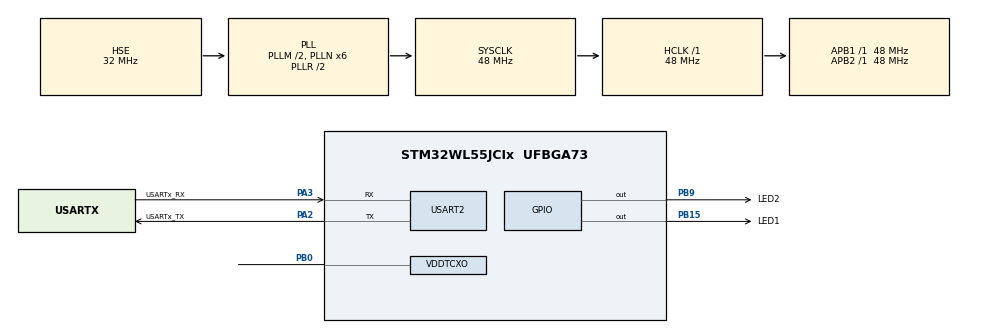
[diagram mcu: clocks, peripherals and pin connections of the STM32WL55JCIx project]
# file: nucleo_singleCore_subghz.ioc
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Mcu.Family=STM32WL
Mcu.Name=STM32WL55JCIx
Mcu.Package=UFBGA73
Mcu.UserConstants=RTC_PREDIV_A,((1<<(15-RTC_N_PREDIV_S))-1);RTC_N_PREDIV_S,10;RTC_PREDIV_S,((1<<RTC_N_PREDIV_S)-1)
NVIC.PriorityGroup=NVIC_PRIORITYGROUP_4
NVIC.SUBGHZ_Radio_IRQn=true\:0\:0\:false\:false\:true\:true\:true\:true
NVIC.USART2_IRQn=true\:0\:0\:false\:false\:true\:true\:true\:true
OSC_IN.Mode=HSE-TCXO
OSC_IN.Signal=RCC_OSC_IN
PA2.GPIO_Label=USARTx_TX
PA2.GPIO_Speed=GPIO_SPEED_FREQ_VERY_HIGH
PA2.Mode=Asynchronous
PA2.Signal=USART2_TX
PA3.GPIO_Label=USARTx_RX
PA3.GPIO_Speed=GPIO_SPEED_FREQ_VERY_HIGH
PA3.Mode=Asynchronous
PA3.Signal=USART2_RX
PB0-VDD_TCXO.Mode=HSE-TCXO
PB0-VDD_TCXO.Signal=VDDTCXO
PB15.GPIO_Label=LED1
PB15.GPIO_Speed=GPIO_SPEED_FREQ_HIGH
PB15.Signal=GPIO_Output
PB9.GPIO_Label=LED2
PB9.GPIO_Speed=GPIO_SPEED_FREQ_HIGH
PB9.Signal=GPIO_Output
PC14-OSC32_IN.Mode=LSE-External-Oscillator
PC14-OSC32_IN.Signal=RCC_OSC32_IN
PC15-OSC32_OUT.Mode=LSE-External-Oscillator
PC15-OSC32_OUT.Signal=RCC_OSC32_OUT
ProjectManager.HeapSize=0x200
ProjectManager.StackSize=0x400
ProjectManager.TargetToolchain=CMake
RCC.AHBFreq_Value=48000000
RCC.APB1Freq_Value=48000000
RCC.APB1TimFreq_Value=48000000
RCC.APB2Freq_Value=48000000
RCC.APB2TimFreq_Value=48000000
RCC.APB3Freq_Value=48000000
RCC.CortexFreq_Value=48000000
RCC.FLatency=FLASH_LATENCY_2
RCC.HCLKFreq_Value=48000000
RCC.HSE_VALUE=32000000
RCC.HSI_VALUE=16000000
RCC.LSE_VALUE=32768
RCC.MSIClockRange=RCC_MSIRANGE_11
RCC.PLLM=RCC_PLLM_DIV2
RCC.PLLN=6
RCC.PLLSourceVirtual=RCC_PLLSOURCE_HSE
RCC.PWR_Regulator_Voltage_Scale=PWR_REGULATOR_VOLTAGE_SCALE1
RCC.RTCClockSelection=RCC_RTCCLKSOURCE_LSE
RCC.SYSCLKFreq_VALUE=48000000
RCC.SYSCLKSource=RCC_SYSCLKSOURCE_PLLCLK
RCC.USART2CLockSelection=RCC_USART2CLKSOURCE_SYSCLK
RCC.VCOOutputFreq_Value=96000000
SUBGHZ.BaudratePrescaler=SUBGHZSPI_BAUDRATEPRESCALER_4
SUBGHZ_PHY.Activate_RADIO_BOARD_INTERFACE=Bsp
SUBGHZ_PHY.SUBGHZ_APPLICATION=SUBGHZ_USER_APPLICATION
SUBGHZ_PHY.USE_UART=true
SubGHz_Phy.BSP.number=1
SubGHz_Phy0.BSP.STBoard=false
SubGHz_Phy0.BSP.api=Unknown
SubGHz_Phy0.BSP.condition=\!SEM_SUBGHZ_USER_APPLICATION | SEM_SUBGHZ_USE_UART
SubGHz_Phy0.BSP.instance=USART2
SubGHz_Phy0.BSP.ip=(LPU|US)ART
SubGHz_Phy0.BSP.mode=Asynchronous
SubGHz_Phy0.BSP.name=USART
SubGHz_Phy0.BSP.solution=USART2
USART2.VirtualMode-Asynchronous=VM_ASYNC
VP_ADV_TRACE_VS_ADV_TRACE.Mode=ADV_TRACE_Enabled
VP_MISC_VS_MISC.Mode=MISC_Enabled
VP_SEQUENCER_M4_VS_SEQUENCER.Mode=SEQUENCER_Enabled
VP_SUBGHZ_PHY_VS_SubGhzPhy.Mode=SubGhzPhy_Enabled
VP_SUBGHZ_VS_SUBGHZ.Mode=SUBGHZ_Activate
VP_TIMER_VS_TIMER.Mode=TIMER_Enabled
VP_TINY_LPM_VS_TINY_LPM.Mode=TINY_LPM_Enabled
board=custom

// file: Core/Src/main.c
/* USER CODE BEGIN Header */
/**
 ******************************************************************************
 * @file           : main.c
 * @brief          : Main program body
 ******************************************************************************
 * @attention
 *
 * Copyright (c) 2026 STMicroelectronics.
 * All rights reserved.
 *
 * This software is licensed under terms that can be found in the LICENSE file
 * in the root directory of this software component.
 * If no LICENSE file comes with this software, it is provided AS-IS.
 *
 ******************************************************************************
 */
/* USER CODE END Header */
#include "main.h"
#include "app_subghz_phy.h"

/* USER CODE BEGIN Includes */
#include <stdint.h>
#include <stdio.h>
/* USER CODE END Includes */

SUBGHZ_HandleTypeDef hsubghz;

UART_HandleTypeDef huart2;

void SystemClock_Config(void);
static void MX_GPIO_Init(void);
/* USER CODE BEGIN PFP */

int __io_putchar(int ch)
{
  HAL_UART_Transmit(&huart2, (uint8_t *)&ch, 1, HAL_MAX_DELAY);
  return ch;
}

/* USER CODE END PFP */

int main(void)
{

  /* MCU Configuration--------------------------------------------------------*/

  /* Reset of all peripherals, Initializes the Flash interface and the Systick. */
  HAL_Init();

  /* Configure the system clock */
  SystemClock_Config();

  /* USER CODE BEGIN SysInit */
  MX_USART2_UART_Init();

  /* USER CODE END SysInit */

  /* Initialize all configured peripherals */
  MX_GPIO_Init();
  MX_SubGHz_Phy_Init();

  /* Infinite loop */
  while (1)
  {
    MX_SubGHz_Phy_Process();

  }
}

void SystemClock_Config(void)
{
  RCC_OscInitTypeDef RCC_OscInitStruct = {0};
  RCC_ClkInitTypeDef RCC_ClkInitStruct = {0};

  /** Configure the main internal regulator output voltage
  */
  __HAL_PWR_VOLTAGESCALING_CONFIG(PWR_REGULATOR_VOLTAGE_SCALE1);

  /** Initializes the CPU, AHB and APB buses clocks
  */
  RCC_OscInitStruct.OscillatorType = RCC_OSCILLATORTYPE_HSE;
  RCC_OscInitStruct.HSEState = RCC_HSE_BYPASS_PWR;
  RCC_OscInitStruct.HSEDiv = RCC_HSE_DIV1;
  RCC_OscInitStruct.PLL.PLLState = RCC_PLL_ON;
  RCC_OscInitStruct.PLL.PLLSource = RCC_PLLSOURCE_HSE;
  RCC_OscInitStruct.PLL.PLLM = RCC_PLLM_DIV2;
  RCC_OscInitStruct.PLL.PLLN = 6;
  RCC_OscInitStruct.PLL.PLLP = RCC_PLLP_DIV2;
  RCC_OscInitStruct.PLL.PLLR = RCC_PLLR_DIV2;
  RCC_OscInitStruct.PLL.PLLQ = RCC_PLLQ_DIV2;
  if (HAL_RCC_OscConfig(&RCC_OscInitStruct) != HAL_OK)
  {
    Error_Handler();
  }

  /** Configure the SYSCLKSource, HCLK, PCLK1 and PCLK2 clocks dividers
  */
  RCC_ClkInitStruct.ClockType = RCC_CLOCKTYPE_HCLK3|RCC_CLOCKTYPE_HCLK
                              |RCC_CLOCKTYPE_SYSCLK|RCC_CLOCKTYPE_PCLK1
                              |RCC_CLOCKTYPE_PCLK2;
  RCC_ClkInitStruct.SYSCLKSource = RCC_SYSCLKSOURCE_PLLCLK;
  RCC_ClkInitStruct.AHBCLKDivider = RCC_SYSCLK_DIV1;
  RCC_ClkInitStruct.APB1CLKDivider = RCC_HCLK_DIV1;
  RCC_ClkInitStruct.APB2CLKDivider = RCC_HCLK_DIV1;
  RCC_ClkInitStruct.AHBCLK3Divider = RCC_SYSCLK_DIV1;

  if (HAL_RCC_ClockConfig(&RCC_ClkInitStruct, FLASH_LATENCY_2) != HAL_OK)
  {
    Error_Handler();
  }
}

void MX_SUBGHZ_Init(void)
{

  hsubghz.Init.BaudratePrescaler = SUBGHZSPI_BAUDRATEPRESCALER_4;
  if (HAL_SUBGHZ_Init(&hsubghz) != HAL_OK)
  {
    Error_Handler();
  }

}

void MX_USART2_UART_Init(void)
{

  huart2.Instance = USART2;
  huart2.Init.BaudRate = 115200;
  huart2.Init.WordLength = UART_WORDLENGTH_8B;
  huart2.Init.StopBits = UART_STOPBITS_1;
  huart2.Init.Parity = UART_PARITY_NONE;
  huart2.Init.Mode = UART_MODE_TX_RX;
  huart2.Init.HwFlowCtl = UART_HWCONTROL_NONE;
  huart2.Init.OverSampling = UART_OVERSAMPLING_16;
  huart2.Init.OneBitSampling = UART_ONE_BIT_SAMPLE_DISABLE;
  huart2.Init.ClockPrescaler = UART_PRESCALER_DIV1;
  huart2.AdvancedInit.AdvFeatureInit = UART_ADVFEATURE_NO_INIT;
  if (HAL_UART_Init(&huart2) != HAL_OK)
  {
    Error_Handler();
  }
  if (HAL_UARTEx_SetTxFifoThreshold(&huart2, UART_TXFIFO_THRESHOLD_1_8) != HAL_OK)
  {
    Error_Handler();
  }
  if (HAL_UARTEx_SetRxFifoThreshold(&huart2, UART_RXFIFO_THRESHOLD_1_8) != HAL_OK)
  {
    Error_Handler();
  }
  if (HAL_UARTEx_DisableFifoMode(&huart2) != HAL_OK)
  {
    Error_Handler();
  }

}

static void MX_GPIO_Init(void)
{
  GPIO_InitTypeDef GPIO_InitStruct = {0};

  /* GPIO Ports Clock Enable */
  __HAL_RCC_GPIOB_CLK_ENABLE();
  __HAL_RCC_GPIOC_CLK_ENABLE();
  __HAL_RCC_GPIOA_CLK_ENABLE();

  /*Configure GPIO pin Output Level */
  HAL_GPIO_WritePin(GPIOB, LED1_Pin|LED2_Pin, GPIO_PIN_RESET);

  /*Configure GPIO pins : LED1_Pin LED2_Pin */
  GPIO_InitStruct.Pin = LED1_Pin|LED2_Pin;
  GPIO_InitStruct.Mode = GPIO_MODE_OUTPUT_PP;
  GPIO_InitStruct.Pull = GPIO_NOPULL;
  GPIO_InitStruct.Speed = GPIO_SPEED_FREQ_HIGH;
  HAL_GPIO_Init(GPIOB, &GPIO_InitStruct);

}

void Error_Handler(void)
{
  __disable_irq();
  while (1)
  {
  }
}
#ifdef USE_FULL_ASSERT
/**
  * @brief  Reports the name of the source file and the source line number
  *         where the assert_param error has occurred.
  * @param  file: pointer to the source file name
  * @param  line: assert_param error line source number
  * @retval None
  */
void assert_failed(uint8_t *file, uint32_t line)
{
  /* USER CODE BEGIN 6 */
  /* User can add his own implementation to report the file name and line
     number, ex: printf("Wrong parameters value: file %s on line %d\r\n", file,
     line) */
  /* USER CODE END 6 */
}
#endif /* USE_FULL_ASSERT */
